# MCU_CPSW0_NUSS_SS register map
Vendor: Texas Instruments
Peripheral module from a debugger description file (folder J7VCL).
Registers are 32-bit, read-write, reset 0x0 unless marked. A register's access mark holds for its fields unless they carry their own. Offsets are as the file gives them; lines under a group give offsets from that group; [hi:lo] are bit positions; {n}, {i} and the like mark numbered series; 'fields as' and 'values as' point back to an identical list; <NAME> marks a mode.

## MCU_CPSW0_NUSS_SS
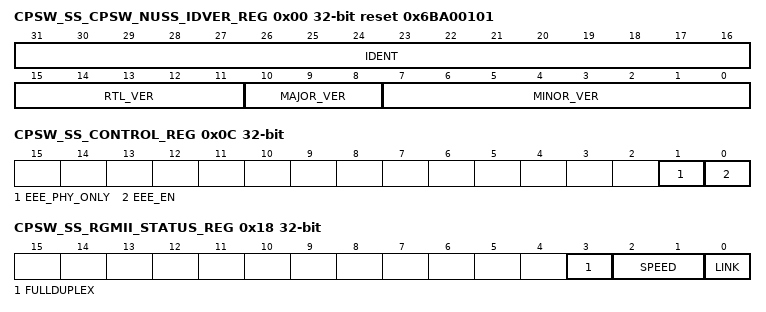
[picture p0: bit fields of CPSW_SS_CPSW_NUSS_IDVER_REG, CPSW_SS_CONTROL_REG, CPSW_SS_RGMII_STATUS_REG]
0x00 CPSW_SS_CPSW_NUSS_IDVER_REG ro reset 0x6BA00101 — CPSW_NUSS ID Version Register
  [31:16] IDENT — Identification value
  [15:11] RTL_VER — RTL version value
  [10:8] MAJOR_VER — Major version value
  [7:0] MINOR_VER — Minor version value
0x04 CPSW_SS_SYNCE_COUNT_REG — CPSW_NUSS SYNCE Count Register
  [31:0] SYNCE_CNT — Sync E Count Value
0x08 CPSW_SS_SYNCE_MUX_REG — CPSW_NUSS Synce Mux Register
  [5:0] SYNCE_SEL — Sync E Select Value
0x0C CPSW_SS_CONTROL_REG — CPSW_NUSS Control Register
  [1] EEE_PHY_ONLY — Energy Efficient Enable Phy Only Mode:0=The low power indicate state includes gating off the CPPI_GCLK to the CPSW, 1=The low power indicate state does not gate the clock to the CPSW
  [0] EEE_EN — Energy Efficient Ethernet Enable:0=EEE is disabled, 1=EEE is enabled
0x10 CPSW_SS_SGMII_MODE_REG reset 0x1 — CPSW_NUSS SyncE Mux Register Note: SGMII mode is not supported on the 2-port CPSW module.
  [0] SYNCE_SEL — SGMII_MODE InputNote: SGMII mode is not supported on the 2-port CPSW module.
0x18 CPSW_SS_RGMII_STATUS_REG ro — CPSW_NUSS RGMII Status Register
  [3] FULLDUPLEX — Rgmii full dulex:0=Half-duplex, 1=Full-duplex
  [2:1] SPEED — Rgmii speed:00=10Mbps, 01=100Mbps, 10=1000Mbps, 11=reserved
  [0] LINK — Rgmii link indicator:0=Link is down, 1=Link is up
0x1C CPSW_SS_SUBSSYSTEM_STATUS_REG ro — CPSW_NUSS Status Register
  [0] EEE_CLKSTOP_ACK — Energy Efficient Ethernet clockstop acknowledge from CPSW
